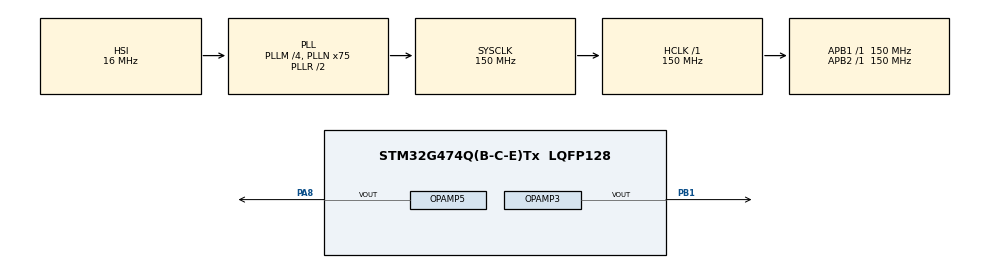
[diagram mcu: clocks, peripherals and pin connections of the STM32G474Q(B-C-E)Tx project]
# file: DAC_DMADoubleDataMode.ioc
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DAC3.DAC_Channel-DAC_OUT2_Int=DAC_CHANNEL_2
DAC3.DAC_OutputBuffer-DAC_OUT2_Int=DAC_OUTPUTBUFFER_DISABLE
DAC3.DAC_Trigger_OUT2-DAC_OUT2_Int=DAC_TRIGGER_T2_TRGO
DAC4.DAC_Channel-DAC_OUT2_Int=DAC_CHANNEL_2
DAC4.DAC_OutputBuffer-DAC_OUT2_Int=DAC_OUTPUTBUFFER_DISABLE
DAC4.DAC_Trigger_OUT2-DAC_OUT2_Int=DAC_TRIGGER_T2_TRGO
Dma.DAC3_CH2.1.Direction=DMA_MEMORY_TO_PERIPH
Dma.DAC3_CH2.1.EventEnable=DISABLE
Dma.DAC3_CH2.1.Instance=DMA1_Channel1
Dma.DAC3_CH2.1.MemDataAlignment=DMA_MDATAALIGN_WORD
Dma.DAC3_CH2.1.MemInc=DMA_MINC_ENABLE
Dma.DAC3_CH2.1.Mode=DMA_CIRCULAR
Dma.DAC3_CH2.1.PeriphDataAlignment=DMA_PDATAALIGN_WORD
Dma.DAC3_CH2.1.PeriphInc=DMA_PINC_DISABLE
Dma.DAC3_CH2.1.Polarity=HAL_DMAMUX_REQ_GEN_RISING
Dma.DAC3_CH2.1.Priority=DMA_PRIORITY_VERY_HIGH
Dma.DAC3_CH2.1.RequestNumber=1
Dma.DAC3_CH2.1.SignalID=NONE
Dma.DAC3_CH2.1.SyncEnable=DISABLE
Dma.DAC3_CH2.1.SyncPolarity=HAL_DMAMUX_SYNC_NO_EVENT
Dma.DAC3_CH2.1.SyncRequestNumber=1
Dma.DAC3_CH2.1.SyncSignalID=NONE
Dma.DAC4_CH2.0.Direction=DMA_MEMORY_TO_PERIPH
Dma.DAC4_CH2.0.EventEnable=DISABLE
Dma.DAC4_CH2.0.Instance=DMA2_Channel1
Dma.DAC4_CH2.0.MemDataAlignment=DMA_MDATAALIGN_WORD
Dma.DAC4_CH2.0.MemInc=DMA_MINC_ENABLE
Dma.DAC4_CH2.0.Mode=DMA_CIRCULAR
Dma.DAC4_CH2.0.PeriphDataAlignment=DMA_PDATAALIGN_WORD
Dma.DAC4_CH2.0.PeriphInc=DMA_PINC_DISABLE
Dma.DAC4_CH2.0.Polarity=HAL_DMAMUX_REQ_GEN_RISING
Dma.DAC4_CH2.0.Priority=DMA_PRIORITY_VERY_HIGH
Dma.DAC4_CH2.0.RequestNumber=1
Dma.DAC4_CH2.0.SignalID=NONE
Dma.DAC4_CH2.0.SyncEnable=DISABLE
Dma.DAC4_CH2.0.SyncPolarity=HAL_DMAMUX_SYNC_NO_EVENT
Dma.DAC4_CH2.0.SyncRequestNumber=1
Dma.DAC4_CH2.0.SyncSignalID=NONE
Dma.Request0=DAC4_CH2
Dma.Request1=DAC3_CH2
Mcu.Family=STM32G4
Mcu.Name=STM32G474Q(B-C-E)Tx
Mcu.Package=LQFP128
NVIC.DMA1_Channel1_IRQn=true\:0\:0\:false\:false\:true\:false\:true\:true
NVIC.DMA2_Channel1_IRQn=true\:0\:0\:false\:false\:true\:false\:true\:true
NVIC.PriorityGroup=NVIC_PRIORITYGROUP_4
OPAMP3.PowerMode=OPAMP_POWERMODE_HIGHSPEED
OPAMP5.PowerMode=OPAMP_POWERMODE_HIGHSPEED
PA8.Mode=Follower-DAC_OUT2-INP
PA8.Signal=OPAMP5_VOUT
PB1.Mode=Follower-DAC_OUT2-INP
PB1.Signal=OPAMP3_VOUT
ProjectManager.HeapSize=0x200
ProjectManager.StackSize=0x400
ProjectManager.TargetToolchain=EWARM V8.32
RCC.ADC12Freq_Value=150000000
RCC.ADC345Freq_Value=150000000
RCC.AHBFreq_Value=150000000
RCC.APB1Freq_Value=150000000
RCC.APB1TimFreq_Value=150000000
RCC.APB2Freq_Value=150000000
RCC.APB2TimFreq_Value=150000000
RCC.CortexFreq_Value=150000000
RCC.EXTERNAL_CLOCK_VALUE=12288000
RCC.HCLKFreq_Value=150000000
RCC.HSE_VALUE=24000000
RCC.HSI48_VALUE=48000000
RCC.HSI_VALUE=16000000
RCC.LSE_VALUE=32768
RCC.PLLM=RCC_PLLM_DIV4
RCC.PLLN=75
RCC.SYSCLKFreq_VALUE=150000000
RCC.SYSCLKSource=RCC_SYSCLKSOURCE_PLLCLK
RCC.USBFreq_Value=150000000
RCC.VCOOutputFreq_Value=300000000
TIM2.AutoReloadPreload=TIM_AUTORELOAD_PRELOAD_DISABLE
TIM2.ClockDivision=TIM_CLOCKDIVISION_DIV1
TIM2.CounterMode=TIM_COUNTERMODE_UP
TIM2.Dithering=Disable
TIM2.PeriodNoDither=9
TIM2.Prescaler=0
TIM2.TIM_MasterOutputTrigger=TIM_TRGO_UPDATE
TIM2.TIM_MasterSlaveMode=TIM_MASTERSLAVEMODE_DISABLE
VP_DAC3_VS_DACI2.Mode=DAC_OUT2_Int
VP_DAC4_VS_DACI2.Mode=DAC_OUT2_Int
VP_SYS_VS_DBSignals.Mode=DisableDeadBatterySignals
VP_TIM2_VS_ClockSourceINT.Mode=Internal
board=custom

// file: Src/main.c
/* USER CODE BEGIN Header */
/**
  ******************************************************************************
  * @file    Examples/DAC/DAC_DMADoubleDataMode/Src/main.c
  * @author  MCD Application Team
  * @brief   This example provides a short description of how to use the ADC
  *          peripheral with sequencer, to convert several channels.
  *          Channels converted are 1 channel on external pin and 2 internal
  *          channels (VrefInt and temperature sensor).
  *          Moreover, voltage and temperature are then computed.
  ******************************************************************************
  * @attention
  *
  * Copyright (c) 2019 STMicroelectronics.
  * All rights reserved.
  *
  * This software is licensed under terms that can be found in the LICENSE file
  * in the root directory of this software component.
  * If no LICENSE file comes with this software, it is provided AS-IS.
  *
  ******************************************************************************
  */
/* USER CODE END Header */
#include "main.h"

/* USER CODE BEGIN Includes */
#include <string.h>
/* USER CODE END Includes */

DAC_HandleTypeDef hdac3;
DAC_HandleTypeDef hdac4;
DMA_HandleTypeDef hdma_dac3_ch2;
DMA_HandleTypeDef hdma_dac4_ch2;

OPAMP_HandleTypeDef hopamp3;
OPAMP_HandleTypeDef hopamp5;

TIM_HandleTypeDef htim2;

/* USER CODE BEGIN PV */
/* Private variables ---------------------------------------------------------*/
DAC_ChannelConfTypeDef DAC3_sconfig;
DAC_ChannelConfTypeDef DAC4_sconfig;

/* Sine wave values for a complete symbol */
uint32_t sinewave[60] = {
0x07ff,0x08cb,0x0994,0x0a5a,0x0b18,0x0bce,0x0c79,0x0d18,0x0da8,0x0e29,0x0e98,0x0ef4,0x0f3e,0x0f72,0x0f92,0x0f9d,
0x0f92,0x0f72,0x0f3e,0x0ef4,0x0e98,0x0e29,0x0da8,0x0d18,0x0c79,0x0bce,0x0b18,0x0a5a,0x0994,0x08cb,0x07ff,0x0733,
0x066a,0x05a4,0x04e6,0x0430,0x0385,0x02e6,0x0256,0x01d5,0x0166,0x010a,0x00c0,0x008c,0x006c,0x0061,0x006c,0x008c,
0x00c0,0x010a,0x0166,0x01d5,0x0256,0x02e6,0x0385,0x0430,0x04e6,0x05a4,0x066a,0x0733};

// DMA Double data mode format
uint32_t sinewave_dmad[30] = {
0x08cb07ff,0x0a5a0994,0x0bce0b18,0x0d180c79,0x0e290da8,0x0ef40e98,0x0f720f3e,0x0f9d0f92,
0x0f720f92,0x0ef40f3e,0x0e290e98,0x0d180da8,0x0bce0c79,0x0a5a0b18,0x08cb0994,0x073307ff,
0x05a4066a,0x043004e6,0x02e60385,0x01d50256,0x010a0166,0x008c00c0,0x0061006c,0x008c006c,
0x010a00c0,0x01d50166,0x02e60256,0x04300385,0x05a404e6,0x0733066a};

FunctionalState vDmaDoubleDataMode = DISABLE;

/* Variable to manage push button on board: interface between ExtLine interruption and main program */
__IO   uint8_t ubUserButtonClickEvent = RESET;  /* Event detection: Set after User Button interrupt */
/* USER CODE END PV */

void SystemClock_Config(void);
static void MX_GPIO_Init(void);
static void MX_DMA_Init(void);
static void MX_DAC3_Init(void);
static void MX_DAC4_Init(void);
static void MX_OPAMP3_Init(void);
static void MX_OPAMP5_Init(void);
static void MX_TIM2_Init(void);

int main(void)
{

  /* MCU Configuration--------------------------------------------------------*/

  /* Reset of all peripherals, Initializes the Flash interface and the Systick. */
  HAL_Init();

  /* Configure the system clock */
  SystemClock_Config();

  /* Initialize all configured peripherals */
  MX_GPIO_Init();
  MX_DMA_Init();
  MX_DAC3_Init();
  MX_DAC4_Init();
  MX_OPAMP3_Init();
  MX_OPAMP5_Init();
  MX_TIM2_Init();
  /* USER CODE BEGIN 2 */

  /* Initialize LED on board */
  BSP_LED_Init(LED1);

  /* Configure User push-button in Interrupt mode */
  BSP_PB_Init(BUTTON_USER, BUTTON_MODE_EXTI);
  /* USER CODE END 2 */

  /* Infinite loop */
  /* USER CODE BEGIN WHILE */

  /*## Start DAC conversions ###############################################*/
  /* Start DAC conversion with DMA */
  if (HAL_DAC_Start_DMA(&hdac3, DAC_CHANNEL_2,
                        (uint32_t *)sinewave,
                        60,
                        DAC_ALIGN_12B_R
                       ) != HAL_OK)
  {
    /* DAC conversion start error */
    Error_Handler();
  }
  if (HAL_DAC_Start_DMA(&hdac4, DAC_CHANNEL_2,
                        (uint32_t *)sinewave,
                        60,
                        DAC_ALIGN_12B_R
                       ) != HAL_OK)
  {
    /* DAC conversion start error */
    Error_Handler();
  }

  /* Start Timer trigger */
  if (HAL_TIM_Base_Start(&htim2) != HAL_OK)
  {
    /* Counter enable error */
    Error_Handler();
  }

  /* Start OPAMP */
  if (HAL_OPAMP_Start(&hopamp3) != HAL_OK)
  {
    /* OPAMP enable error */
    Error_Handler();
  }
  if (HAL_OPAMP_Start(&hopamp5) != HAL_OK)
  {
    /* OPAMP enable error */
    Error_Handler();
  }

  BSP_LED_On(LED1);
  while (1)
  {
    /* Wait for event on push button to perform following actions */
    while ((ubUserButtonClickEvent) == RESET)
    {
    }
    /* Reset variable for next loop iteration (with debounce) */
    HAL_Delay(200);
    ubUserButtonClickEvent = RESET;

    /* Stop DAC conversion with DMA */
    if (HAL_DAC_Stop_DMA(&hdac3, DAC_CHANNEL_2) != HAL_OK)
    {
      /* DAC conversion stop error */
      Error_Handler();
    }
    if (HAL_DAC_Stop_DMA(&hdac4, DAC_CHANNEL_2) != HAL_OK)
    {
      /* DAC conversion stop error */
      Error_Handler();
    }

    /* Stop Timer trigger */
    if (HAL_TIM_Base_Stop(&htim2) != HAL_OK)
    {
      /* Counter disable error */
      Error_Handler();
    }

    if (vDmaDoubleDataMode == DISABLE)
    {
      vDmaDoubleDataMode = ENABLE;

      /* Re configure DAC */
      DAC3_sconfig.DAC_DMADoubleDataMode = vDmaDoubleDataMode;
      DAC4_sconfig.DAC_DMADoubleDataMode = vDmaDoubleDataMode;
      if (HAL_DAC_ConfigChannel(&hdac3, &DAC3_sconfig, DAC_CHANNEL_2) != HAL_OK)
      {
        Error_Handler();
      }
      if (HAL_DAC_ConfigChannel(&hdac4, &DAC4_sconfig, DAC_CHANNEL_2) != HAL_OK)
      {
        Error_Handler();
      }

      /* Start DAC conversion with DMA */
      if (HAL_DAC_Start_DMA(&hdac3, DAC_CHANNEL_2,
                            (uint32_t *)sinewave_dmad,
                            30,
                            DAC_ALIGN_12B_R
                           ) != HAL_OK)
      {
        /* DAC conversion start error */
        Error_Handler();
      }
      if (HAL_DAC_Start_DMA(&hdac4, DAC_CHANNEL_2,
                            (uint32_t *)sinewave_dmad,
                            30,
                            DAC_ALIGN_12B_R
                           ) != HAL_OK)
      {
        /* DAC conversion start error */
        Error_Handler();
      }
    }
    else
    {
      vDmaDoubleDataMode = DISABLE;

      /* Re configure DAC */
      DAC3_sconfig.DAC_DMADoubleDataMode = vDmaDoubleDataMode;
      DAC4_sconfig.DAC_DMADoubleDataMode = vDmaDoubleDataMode;
      if (HAL_DAC_ConfigChannel(&hdac3, &DAC3_sconfig, DAC_CHANNEL_2) != HAL_OK)
      {
        Error_Handler();
      }
      if (HAL_DAC_ConfigChannel(&hdac4, &DAC4_sconfig, DAC_CHANNEL_2) != HAL_OK)
      {
        Error_Handler();
      }

      /* Start DAC conversion with DMA */
      if (HAL_DAC_Start_DMA(&hdac3, DAC_CHANNEL_2,
                            (uint32_t *)sinewave,
                            60,
                            DAC_ALIGN_12B_R
                           ) != HAL_OK)
      {
        /* DAC conversion start error */
        Error_Handler();
      }
      if (HAL_DAC_Start_DMA(&hdac4, DAC_CHANNEL_2,
                            (uint32_t *)sinewave,
                            60,
                            DAC_ALIGN_12B_R
                           ) != HAL_OK)
      {
        /* DAC conversion start error */
        Error_Handler();
      }
    }

    /* Start Timer trigger */
    if (HAL_TIM_Base_Start(&htim2) != HAL_OK)
    {
      /* Counter enable error */
      Error_Handler();
    }

    /* USER CODE END WHILE */

  }
}

void SystemClock_Config(void)
{
  RCC_OscInitTypeDef RCC_OscInitStruct = {0};
  RCC_ClkInitTypeDef RCC_ClkInitStruct = {0};

  /** Configure the main internal regulator output voltage
  */
  HAL_PWREx_ControlVoltageScaling(PWR_REGULATOR_VOLTAGE_SCALE1);

  /** Initializes the RCC Oscillators according to the specified parameters
  * in the RCC_OscInitTypeDef structure.
  */
  RCC_OscInitStruct.OscillatorType = RCC_OSCILLATORTYPE_HSI;
  RCC_OscInitStruct.HSIState = RCC_HSI_ON;
  RCC_OscInitStruct.HSICalibrationValue = RCC_HSICALIBRATION_DEFAULT;
  RCC_OscInitStruct.PLL.PLLState = RCC_PLL_ON;
  RCC_OscInitStruct.PLL.PLLSource = RCC_PLLSOURCE_HSI;
  RCC_OscInitStruct.PLL.PLLM = RCC_PLLM_DIV4;
  RCC_OscInitStruct.PLL.PLLN = 75;
  RCC_OscInitStruct.PLL.PLLP = RCC_PLLP_DIV2;
  RCC_OscInitStruct.PLL.PLLQ = RCC_PLLQ_DIV2;
  RCC_OscInitStruct.PLL.PLLR = RCC_PLLR_DIV2;
  if (HAL_RCC_OscConfig(&RCC_OscInitStruct) != HAL_OK)
  {
    Error_Handler();
  }

  /** Initializes the CPU, AHB and APB buses clocks
  */
  RCC_ClkInitStruct.ClockType = RCC_CLOCKTYPE_HCLK|RCC_CLOCKTYPE_SYSCLK
                              |RCC_CLOCKTYPE_PCLK1|RCC_CLOCKTYPE_PCLK2;
  RCC_ClkInitStruct.SYSCLKSource = RCC_SYSCLKSOURCE_PLLCLK;
  RCC_ClkInitStruct.AHBCLKDivider = RCC_SYSCLK_DIV1;
  RCC_ClkInitStruct.APB1CLKDivider = RCC_HCLK_DIV1;
  RCC_ClkInitStruct.APB2CLKDivider = RCC_HCLK_DIV1;

  if (HAL_RCC_ClockConfig(&RCC_ClkInitStruct, FLASH_LATENCY_4) != HAL_OK)
  {
    Error_Handler();
  }
}

static void MX_DAC3_Init(void)
{

  DAC_ChannelConfTypeDef sConfig = {0};

  /** DAC Initialization
  */
  hdac3.Instance = DAC3;
  if (HAL_DAC_Init(&hdac3) != HAL_OK)
  {
    Error_Handler();
  }

  /** DAC channel OUT2 config
  */
  sConfig.DAC_HighFrequency = DAC_HIGH_FREQUENCY_INTERFACE_MODE_AUTOMATIC;
  sConfig.DAC_DMADoubleDataMode = DISABLE;
  sConfig.DAC_SignedFormat = DISABLE;
  sConfig.DAC_SampleAndHold = DAC_SAMPLEANDHOLD_DISABLE;
  sConfig.DAC_Trigger = DAC_TRIGGER_T2_TRGO;
  sConfig.DAC_Trigger2 = DAC_TRIGGER_NONE;
  sConfig.DAC_OutputBuffer = DAC_OUTPUTBUFFER_DISABLE;
  sConfig.DAC_ConnectOnChipPeripheral = DAC_CHIPCONNECT_INTERNAL;
  sConfig.DAC_UserTrimming = DAC_TRIMMING_FACTORY;
  if (HAL_DAC_ConfigChannel(&hdac3, &sConfig, DAC_CHANNEL_2) != HAL_OK)
  {
    Error_Handler();
  }
  /* USER CODE BEGIN DAC3_Init 2 */
  memcpy((void *)&DAC3_sconfig, &sConfig, sizeof(DAC_ChannelConfTypeDef));
  /* USER CODE END DAC3_Init 2 */

}

static void MX_DAC4_Init(void)
{

  DAC_ChannelConfTypeDef sConfig = {0};

  /** DAC Initialization
  */
  hdac4.Instance = DAC4;
  if (HAL_DAC_Init(&hdac4) != HAL_OK)
  {
    Error_Handler();
  }

  /** DAC channel OUT2 config
  */
  sConfig.DAC_HighFrequency = DAC_HIGH_FREQUENCY_INTERFACE_MODE_AUTOMATIC;
  sConfig.DAC_DMADoubleDataMode = DISABLE;
  sConfig.DAC_SignedFormat = DISABLE;
  sConfig.DAC_SampleAndHold = DAC_SAMPLEANDHOLD_DISABLE;
  sConfig.DAC_Trigger = DAC_TRIGGER_T2_TRGO;
  sConfig.DAC_Trigger2 = DAC_TRIGGER_NONE;
  sConfig.DAC_OutputBuffer = DAC_OUTPUTBUFFER_DISABLE;
  sConfig.DAC_ConnectOnChipPeripheral = DAC_CHIPCONNECT_INTERNAL;
  sConfig.DAC_UserTrimming = DAC_TRIMMING_FACTORY;
  if (HAL_DAC_ConfigChannel(&hdac4, &sConfig, DAC_CHANNEL_2) != HAL_OK)
  {
    Error_Handler();
  }
  /* USER CODE BEGIN DAC4_Init 2 */
  memcpy((void *)&DAC4_sconfig, &sConfig, sizeof(DAC_ChannelConfTypeDef));
  /* USER CODE END DAC4_Init 2 */

}

static void MX_OPAMP3_Init(void)
{

  hopamp3.Instance = OPAMP3;
  hopamp3.Init.PowerMode = OPAMP_POWERMODE_HIGHSPEED;
  hopamp3.Init.Mode = OPAMP_FOLLOWER_MODE;
  hopamp3.Init.NonInvertingInput = OPAMP_NONINVERTINGINPUT_DAC;
  hopamp3.Init.InternalOutput = DISABLE;
  hopamp3.Init.TimerControlledMuxmode = OPAMP_TIMERCONTROLLEDMUXMODE_DISABLE;
  hopamp3.Init.UserTrimming = OPAMP_TRIMMING_FACTORY;
  if (HAL_OPAMP_Init(&hopamp3) != HAL_OK)
  {
    Error_Handler();
  }

}

static void MX_OPAMP5_Init(void)
{

  hopamp5.Instance = OPAMP5;
  hopamp5.Init.PowerMode = OPAMP_POWERMODE_HIGHSPEED;
  hopamp5.Init.Mode = OPAMP_FOLLOWER_MODE;
  hopamp5.Init.NonInvertingInput = OPAMP_NONINVERTINGINPUT_DAC;
  hopamp5.Init.InternalOutput = DISABLE;
  hopamp5.Init.TimerControlledMuxmode = OPAMP_TIMERCONTROLLEDMUXMODE_DISABLE;
  hopamp5.Init.UserTrimming = OPAMP_TRIMMING_FACTORY;
  if (HAL_OPAMP_Init(&hopamp5) != HAL_OK)
  {
    Error_Handler();
  }

}

static void MX_TIM2_Init(void)
{

  TIM_ClockConfigTypeDef sClockSourceConfig = {0};
  TIM_MasterConfigTypeDef sMasterConfig = {0};

  htim2.Instance = TIM2;
  htim2.Init.Prescaler = 0;
  htim2.Init.CounterMode = TIM_COUNTERMODE_UP;
  htim2.Init.Period = 9;
  htim2.Init.ClockDivision = TIM_CLOCKDIVISION_DIV1;
  htim2.Init.AutoReloadPreload = TIM_AUTORELOAD_PRELOAD_DISABLE;
  if (HAL_TIM_Base_Init(&htim2) != HAL_OK)
  {
    Error_Handler();
  }
  sClockSourceConfig.ClockSource = TIM_CLOCKSOURCE_INTERNAL;
  if (HAL_TIM_ConfigClockSource(&htim2, &sClockSourceConfig) != HAL_OK)
  {
    Error_Handler();
  }
  sMasterConfig.MasterOutputTrigger = TIM_TRGO_UPDATE;
  sMasterConfig.MasterSlaveMode = TIM_MASTERSLAVEMODE_DISABLE;
  if (HAL_TIMEx_MasterConfigSynchronization(&htim2, &sMasterConfig) != HAL_OK)
  {
    Error_Handler();
  }

}

static void MX_DMA_Init(void)
{

  /* DMA controller clock enable */
  __HAL_RCC_DMAMUX1_CLK_ENABLE();
  __HAL_RCC_DMA2_CLK_ENABLE();
  __HAL_RCC_DMA1_CLK_ENABLE();

  /* DMA interrupt init */
  /* DMA1_Channel1_IRQn interrupt configuration */
  HAL_NVIC_SetPriority(DMA1_Channel1_IRQn, 0, 0);
  HAL_NVIC_EnableIRQ(DMA1_Channel1_IRQn);
  /* DMA2_Channel1_IRQn interrupt configuration */
  HAL_NVIC_SetPriority(DMA2_Channel1_IRQn, 0, 0);
  HAL_NVIC_EnableIRQ(DMA2_Channel1_IRQn);

}

static void MX_GPIO_Init(void)
{

  /* GPIO Ports Clock Enable */
  __HAL_RCC_GPIOB_CLK_ENABLE();
  __HAL_RCC_GPIOA_CLK_ENABLE();

}

/* USER CODE BEGIN 4 */

/******************************************************************************/
/*   USER IRQ HANDLER TREATMENT                                               */
/******************************************************************************/

/**
  * @brief EXTI line detection callbacks
  * @param GPIO_Pin: Specifies the pins connected EXTI line
  * @retval None
  */
void HAL_GPIO_EXTI_Callback(uint16_t GPIO_Pin)
{
 if (GPIO_Pin == USER_BUTTON_PIN)
 {
   /* Set variable to report push button event to main program */
   ubUserButtonClickEvent = SET;
 }
}
/* USER CODE END 4 */

void Error_Handler(void)
{
  /* USER CODE BEGIN Error_Handler_Debug */
  /* User can add his own implementation to report the HAL error return state */
  while(1)
  {
    /* Toggle LED1 */
    BSP_LED_Off(LED1);
    HAL_Delay(800);
    BSP_LED_On(LED1);
    HAL_Delay(10);
    BSP_LED_Off(LED1);
    HAL_Delay(180);
    BSP_LED_On(LED1);
    HAL_Delay(10);
  }
  /* USER CODE END Error_Handler_Debug */
}

#ifdef  USE_FULL_ASSERT
/**
  * @brief  Reports the name of the source file and the source line number
  *         where the assert_param error has occurred.
  * @param  file: pointer to the source file name
  * @param  line: assert_param error line source number
  * @retval None
  */
void assert_failed(uint8_t *file, uint32_t line)
{
  /* USER CODE BEGIN 6 */
  /* User can add his own implementation to report the file name and line number,
     tex: printf("Wrong parameters value: file %s on line %d\r\n", file, line) */
  Error_Handler();
  /* USER CODE END 6 */
}
#endif /* USE_FULL_ASSERT */
